# nrf7140_application register map
Vendor: Nordic Semiconductor; Series: nRF71; File version: 1
CPU: CM33 r0p4, little endian, MPU, FPU, 3 interrupt priority bits, 480 interrupts, 8 SAU regions
Registers are 32-bit, read-write, reset 0x0 unless marked. A register's access mark holds for its fields unless they carry their own. Offsets are from the block's base; [hi:lo] are bit positions; lines under a group give offsets from that group; {n}, {i} and the like mark numbered series; 'fields as' and 'values as' point back to an identical list.

## BICR_NS — Board information configuration registers
Base 0x0FFF8C00
0x00 POWER group — Unspecified
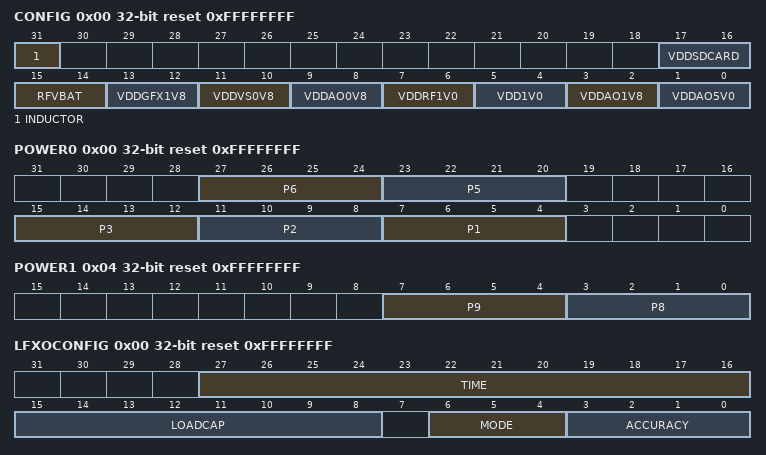
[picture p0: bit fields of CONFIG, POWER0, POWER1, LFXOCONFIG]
  0x00 CONFIG reset 0xFFFFFFFF — Power configuration of power rails.
    [31] INDUCTOR — DC/DC inductor presence.
      1=NotPresent (DC/DC inductor is not present.); 0=Present (DC/DC inductor is present.)
    [17:16] VDDSDCARD — VDD_SDCARD power configuration.
      3=Unconfigured (Power rail is unconfigured.); 0=ExternalFull (Power rail is externally powered at 1.8V / 3.3V externally switchable.); 1=External1v8 (Power rail is externally powered at 1.8V.); 2=External3v3 (Power rail is externally powered at 3.3V.)
    [15:14] RFVBAT — RFVBAT_AFEVBAT power configuration.
      3=Unconfigured (Power rail is unconfigured or disconnected.); 1=External (Power rail is configured to be externally powered.)
    [13:12] VDDGFX1V8 — VDD_GFX_1V8 power configuration.
      values as RFVBAT
    [11:10] VDDVS0V8 — VDD_VS_0V8 power configuration.
      3=Unconfigured (Power rail is unconfigured.); 0=Internal (Power rail is configured to use the internal regulator.); 1=External (Power rail is configured to be externally powered.)
    [9:8] VDDAO0V8 — VDD_AO_0V8 power configuration.
      values as VDDVS0V8
    [7:6] VDDRF1V0 — VDD_RF_1V0 power configuration.
      3=Unconfigured (Power rail is unconfigured or disconnected.); 1=External (Power rail is configured to be externally powered.); 2=Shorted (Power rail is shorted to VDD_1V0.)
    [5:4] VDD1V0 — VDD_1V0 power configuration.
      values as VDDVS0V8
    [3:2] VDDAO1V8 — VDD_AO_1V8 power configuration.
      values as VDDVS0V8
    [1:0] VDDAO5V0 — VDD_AO_5V0 power configuration.
      3=Unconfigured (Power rail is unconfigured.); 1=External (Power rail is configured to be externally powered.); 2=Shorted (Power rail is shorted to VDD_AO_1V8. Can only be used if VDDAO1V8 field is External.)
0x04 IOPORT group — Unspecified
  0x00 POWER0 reset 0xFFFFFFFF — Power configuration for P0 to P7 IO ports. Note: P0 is not included in the fields of this register because it is always internally supplied and therefore considered 'Shorted'.
    [all] fields
      15=Unconfigured (Port supply is unconfigured.); 0=Disconnected (Port supply rail is not connected. Port cannot be used.); 1=Shorted (Port supply is shorted to VDD_AO_1V8.); 2=External1V8 (Port supply is provided externally at 1.8 V.)
    [27:24] P6 — P6 power configuration.
    [23:20] P5 — P5 power configuration.
    [15:12] P3 — P3 power configuration.
    [11:8] P2 — P2 power configuration.
    [7:4] P1 — P1 power configuration.
  0x04 POWER1 reset 0xFFFFFFFF — Power configuration for P8 to P15 IO ports.
    [7:4] P9 — P9 power configuration.
      15=Unconfigured (Port supply is unconfigured.); 0=Disconnected (Port supply rail is not connected. Port cannot be used.); 1=Shorted (Port supply is shorted to VDD_AO_1V8.); 2=External1V8 (Port supply is provided externally at 1.8 V.); 3=External3V (Port supply is provided externally at 3 V.); 4=ExternalFull (Port supply is provided externally with a full range of values, from 3 V to 1.8 V.)
    [3:0] P8 — P8 power configuration.
      values as the fields of IOPORT.POWER0
  0x08 DRIVECTRL0 reset 0xFFFFFFFF — Drive control configuration for P0 to P7 IO ports.
    [27:24] P6 — P6 drive control configuration.
      15=Unconfigured (Port supply is unconfigured. PORTCNF.DRIVECTRL will not be adjusted.); 0=Ohms33 (PORTCNF.DRIVECTRL will be adjusted for 33 Ohms.); 1=Ohms40 (PORTCNF.DRIVECTRL will be adjusted for 40 Ohms.); 2=Ohms50 (PORTCNF.DRIVECTRL will be adjusted for 50 Ohms.); 3=Ohms66 (PORTCNF.DRIVECTRL will be adjusted for 66 Ohms.); 4=Ohms100 (PORTCNF.DRIVECTRL will be adjusted for 100 Ohms.)
  0x0C DRIVECTRL1 reset 0xFFFFFFFF — Drive control configuration for P8 to P15 IO ports.
    [3:0] P8 — P8 drive control configuration.
      values as IOPORT.DRIVECTRL0.P6
  0x10 BIASCTRL0 reset 0xFFFFFFFF — Bias control configuration for P0 to P7 IO ports.
    [23:20] P5 — P5 bias control configuration.
      15=Unconfigured (Port supply is unconfigured. PORTCNF.BIASCTRL will not be adjusted.); 0=Freq24 (PORTCNF.BIASCTRL will be adjusted for frequency range 8MHz to 24MHz.); 1=Freq48 (PORTCNF.BIASCTRL will be adjusted for frequency range 24MHz to 48MHz.); 2=Freq72 (PORTCNF.BIASCTRL will be adjusted for frequency range 48MHz to 72MHz.); 3=Freq100 (PORTCNF.BIASCTRL will be adjusted for frequency range 72MHz to 100MHz.)
0x18 LFOSC group — Unspecified
  0x00 LFXOCONFIG reset 0xFFFFFFFF — LFXO configuration.
    [27:16] TIME — LFXO startup time in ms.
      0xFFF=Unconfigured (Startup time has not been configured.)
    [15:8] LOADCAP — Built-in load capacitors selection in 1 pF steps. Max. value 25 pF.
      255=Unconfigured (The built-in load capacitors is unconfigured. LFXO will not start unless LOADCAP is configured.); 0=External (Do not use the built-in load capacitors, only external capacitors will be used.)
    [6:4] MODE — LFXO mode. LFXO will not start unless MODE is configured. Setting this field to anyting but Unconfigured will be used as the indication that the selected source is available as input to the LFXO.
      7=Unconfigured (The mode is unconfigured.); 0=Crystal (LFXO in external crystal oscillator mode.); 2=ExtSine (LFXO in external sine wave mode.); 3=ExtSquare (LFXO in external square wave mode.); 6=Disabled (LFXO is not to be used.)
    [3:0] ACCURACY — LFXO crystal or external signal accuracy.
      15=Unconfigured (The accuracy is unconfigured.); 0=500ppm (LFXO crystal or external signal has an accuracy of 500 ppm.); 1=250ppm (LFXO crystal or external signal has an accuracy of 250 ppm.); 2=150ppm (LFXO crystal or external signal has an accuracy of 150 ppm.); 3=100ppm (LFXO crystal or external signal has an accuracy of 100 ppm.); 4=75ppm (LFXO crystal or external signal has an accuracy of 75 ppm.); 5=50ppm (LFXO crystal or external signal has an accuracy of 50 ppm.); 6=30ppm (LFXO crystal or external signal has an accuracy of 30 ppm.); 7=20ppm (LFXO crystal or external signal has an accuracy of 20 ppm.)
  0x04 LFXOCAL reset 0xFFFFFFFF — LFXO calibration needed. Must be written to 0xFFFFFFFF after any modification of the LFXO board circuit, load capacitance, or crystal swap.
    [31:0] LFXOCAL
      0xFFFFFFFF=Calibrate the LFXO at startup
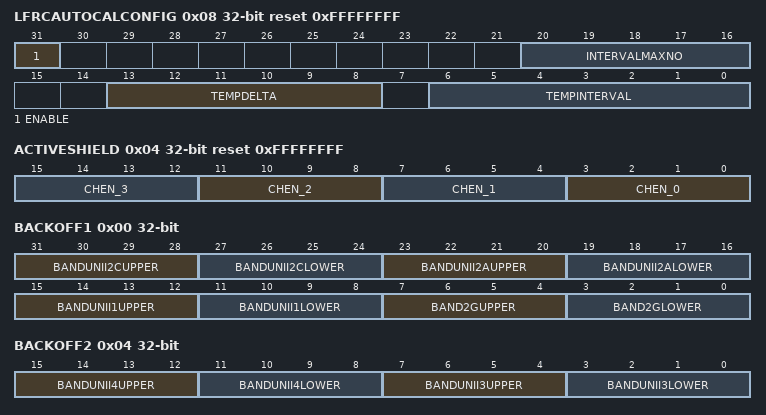
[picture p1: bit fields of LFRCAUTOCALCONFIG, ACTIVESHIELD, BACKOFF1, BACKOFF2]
  0x08 LFRCAUTOCALCONFIG reset 0xFFFFFFFF — LFRC autocalibration configuration.
    [31] ENABLE — LFRC.AUTOCALCONFIG register enable.
      0=Enabled (LFRC.AUTOCALCONFIG register has been configured and can be used.); 1=Disabled (LFRC.AUTOCALCONFIG register has not been configured and cannot be used.)
    [20:16] INTERVALMAXNO — Maximum number of TEMPINTERVAL periods in between calibrations, independent of temperature changes.
    [13:8] TEMPDELTA — Temperature delta that should trigger a calibration in 0.25 degrees steps.
    [6:0] TEMPINTERVAL — Temperature measurement interval in 0.25 s steps.
0x2C HFXO64M group — Unspecified
  0x00 CONFIG reset 0xFFFFFFFF — HFXO64M configuration.
    [2:0] MODE — HFXO64M mode.
      7=Unconfigured (The mode is unconfigured.); 0=Normal operating mode; 1=TCXO (TCXO/bypass mode); {v}=Crystal{v} (Reserved value) (v=2..6)
  0x04 STARTUPTIME reset 0xFFFFFFFF — HFXO64M startup time in us.
    [31:0] TIME
      0xFFFFFFFF=Unconfigured (Startup time has not been configured.)
0x34 TAMPC group — Unspecified
  0x00 TAMPERSWITCH reset 0xFFFFFFFF — Configuration for external tamper switch detector.
    [3:0] TAMPERSWITCH — Tamper switch enable.
      15=Disabled (Tamper switch is disabled.); 0=Enabled (Tamper switch is enabled. Any value but 0xF is to be considered Enabled.)
  0x04 ACTIVESHIELD reset 0xFFFFFFFF — Configuration for active shield channels.
    [4n+3:4n] CHEN_{n} (n=0..3) — Active shield enable for channel {n}.
      15=Disabled (Active shield channel {n} is disabled.); 0=Enabled (Active shield channel {n} is enabled. Any value but 0xF is to be considered Enabled. If any channel is Enabled, the feature should be Enabled.)
0x3C MISPROT group — Unspecified
  0x00 POWERCONFIG reset 0xFFFFFFFF — Misconfiguration report for POWER.CONFIG register.
    [31:0] POWERCONFIG — Misconfiguration report configuration for POWER.CONFIG register.
      0x471B4B2A=Correct (POWER.CONFIG register does not have an invalid field.); 0xAA95E6D8=Incorrect (POWER.CONFIG register has at least an invalid field. POWER.CONFIG register is not used and should be corrected.)
  0x04 IOPORTPOWER reset 0xFFFFFFFF — Misconfiguration report for IOPORT.POWER0 and IOPORT.POWER1 registers.
    [31:0] IOPORTPOWER — Misconfiguration report configuration for IOPORT.POWER0 and IOPORT.POWER1 registers.
      0x471B4B2A=Correct (IOPORT.POWER0 and IOPORT.POWER1 registers do not have an invalid field.); 0xAA95E6D8=Incorrect (IOPORT.POWER0 and/or IOPORT.POWER1 registers have at least an invalid field. Invalid field is not used and should be corrected.)
  0x08 IOPORTDRIVECTRL reset 0xFFFFFFFF — Misconfiguration report for IOPORT.DRIVECTRL0 and IOPORT.DRIVECTRL1 registers.
    [31:0] IOPORTDRIVECTRL0
      0x471B4B2A=Correct (IOPORT.DRIVECTRL0 and IOPORT.DRIVECTRL1 register does not have an invalid field.); 0xAA95E6D8=Incorrect (IOPORT.DRIVECTRL0 and/or and IOPORT.DRIVECTRL1 registers have at least an invalid field. Invalid field is not used and should be corrected.)
0x48 WIFIRADIO group — Unspecified
  0x00 BACKOFF1 — Band edge channel transmit power backoff (in dB) for regulatory bands
    [31:28] BANDUNII2CUPPER — TX power backoff (in dB) for the upper edge of UNII-2C frequency band
    [27:24] BANDUNII2CLOWER — TX power backoff (in dB) for the lower edge of UNII-2C frequency band
    [23:20] BANDUNII2AUPPER — TX power backoff (in dB) for the upper edge of UNII-2A frequency band
    [19:16] BANDUNII2ALOWER — TX power backoff (in dB) for the lower edge of UNII-2A frequency band
    [15:12] BANDUNII1UPPER — TX power backoff (in dB) for the upper edge of UNII-1 frequency band
    [11:8] BANDUNII1LOWER — TX power backoff (in dB) for the lower edge of UNII-1 frequency band
    [7:4] BAND2GUPPER — TX power backoff (in dB) for the upper edge of 2.4GHz frequency band
    [3:0] BAND2GLOWER — TX power backoff (in dB) for the lower edge of 2.4GHz frequency band
  0x04 BACKOFF2 — Band edge channel transmit power backoff (in dB) for regulatory bands
    [15:12] BANDUNII4UPPER — TX power backoff (in dB) for the upper edge of UNII-4 frequency band
    [11:8] BANDUNII4LOWER — TX power backoff (in dB) for the lower edge of UNII-4 frequency band
    [7:4] BANDUNII3UPPER — TX power backoff (in dB) for the upper edge of UNII-3 frequency band
    [3:0] BANDUNII3LOWER — TX power backoff (in dB) for the lower edge of UNII-3 frequency band
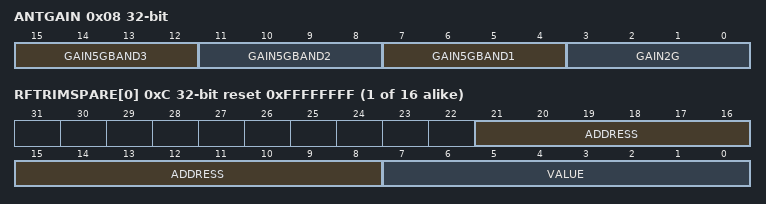
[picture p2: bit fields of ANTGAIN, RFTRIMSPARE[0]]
  0x08 ANTGAIN — Antenna gain (in dB) used to adjust TX power
    [15:12] GAIN5GBAND3 — Antenna gain (in dB) for the 5GHz frequency band 3
    [11:8] GAIN5GBAND2 — Antenna gain (in dB) for the 5GHz frequency band 2
    [7:4] GAIN5GBAND1 — Antenna gain (in dB) for the 5GHz frequency band 1
    [3:0] GAIN2G — Antenna gain (in dB) for the 2.4GHz frequency band
  {0xC+4j} RFTRIMSPARE[{j}] (j=0..15) reset 0xFFFFFFFF — Description collection: Arbitrary RF register trim
    [21:8] ADDRESS — Register address to apply trim value to. Address 0x3FFF indicates unused trim value.
    [7:0] VALUE — Trim value to apply

## Notices in the file
Copyright (c) 2010 - 2024, Nordic Semiconductor ASA
All rights reserved.
Redistribution and use in source and binary forms, with or without modification,
are permitted provided that the following conditions are met:
1. Redistributions of source code must retain the above copyright notice, this
list of conditions and the following disclaimer.
2. Redistributions in binary form, except as embedded into a Nordic
Semiconductor ASA integrated circuit in a product or a software update for
such product, must reproduce the above copyright notice, this list of
conditions and the following disclaimer in the documentation and/or other
materials provided with the distribution.
3. Neither the name of Nordic Semiconductor ASA nor the names of its
contributors may be used to endorse or promote products derived from this
software without specific prior written permission.
4. This software, with or without modification, must only be used with a
Nordic Semiconductor ASA integrated circuit.
5. Any software provided in binary form under this license must not be reverse
engineered, decompiled, modified and/or disassembled.
THIS SOFTWARE IS PROVIDED BY NORDIC SEMICONDUCTOR ASA "AS IS" AND ANY EXPRESS
OR IMPLIED WARRANTIES, INCLUDING, BUT NOT LIMITED TO, THE IMPLIED WARRANTIES
OF MERCHANTABILITY, NONINFRINGEMENT, AND FITNESS FOR A PARTICULAR PURPOSE ARE
DISCLAIMED. IN NO EVENT SHALL NORDIC SEMICONDUCTOR ASA OR CONTRIBUTORS BE
LIABLE FOR ANY DIRECT, INDIRECT, INCIDENTAL, SPECIAL, EXEMPLARY, OR
CONSEQUENTIAL DAMAGES (INCLUDING, BUT NOT LIMITED TO, PROCUREMENT OF SUBSTITUTE
GOODS OR SERVICES; LOSS OF USE, DATA, OR PROFITS; OR BUSINESS INTERRUPTION)
HOWEVER CAUSED AND ON ANY THEORY OF LIABILITY, WHETHER IN CONTRACT, STRICT
LIABILITY, OR TORT (INCLUDING NEGLIGENCE OR OTHERWISE) ARISING IN ANY WAY OUT
OF THE USE OF THIS SOFTWARE, EVEN IF ADVISED OF THE POSSIBILITY OF SUCH DAMAGE.
